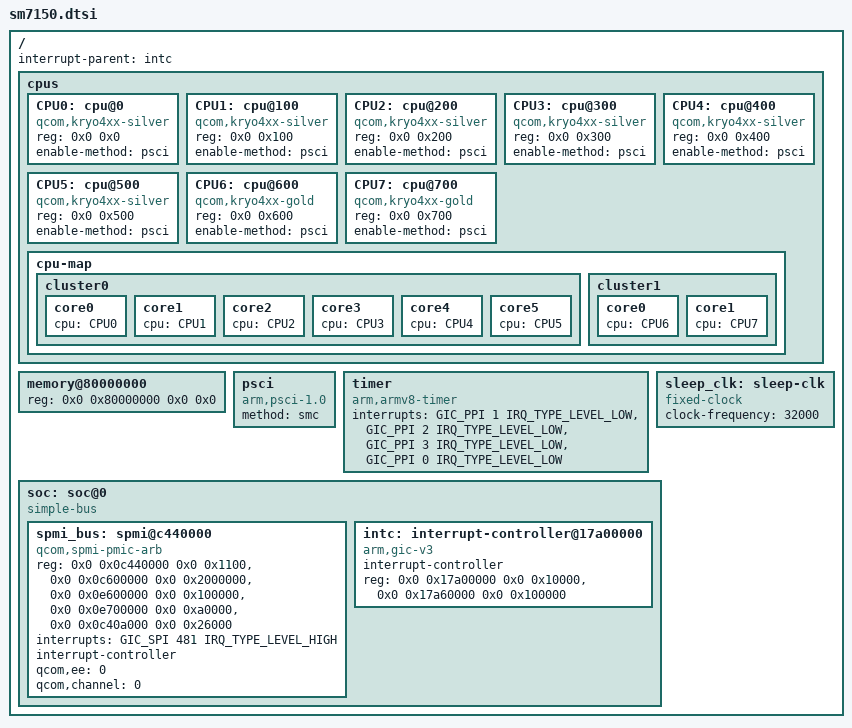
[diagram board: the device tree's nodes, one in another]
// SPDX-License-Identifier: GPL-2.0-only OR BSD-2-Clause

#include <dt-bindings/interrupt-controller/arm-gic.h>

/ {
	#address-cells = <2>;
	#size-cells = <2>;
	interrupt-parent = <&intc>;

	cpus {
		#address-cells = <2>;
		#size-cells = <0>;

		CPU0: cpu@0 {
			device_type = "cpu";
			compatible = "qcom,kryo4xx-silver";
			reg = <0x0 0x0>;
			enable-method = "psci";
		};

		CPU1: cpu@100 {
			device_type = "cpu";
			compatible = "qcom,kryo4xx-silver";
			reg = <0x0 0x100>;
			enable-method = "psci";
		};

		CPU2: cpu@200 {
			device_type = "cpu";
			compatible = "qcom,kryo4xx-silver";
			reg = <0x0 0x200>;
			enable-method = "psci";
		};

		CPU3: cpu@300 {
			device_type = "cpu";
			compatible = "qcom,kryo4xx-silver";
			reg = <0x0 0x300>;
			enable-method = "psci";
		};

		CPU4: cpu@400 {
			device_type = "cpu";
			compatible = "qcom,kryo4xx-silver";
			reg = <0x0 0x400>;
			enable-method = "psci";
		};

		CPU5: cpu@500 {
			device_type = "cpu";
			compatible = "qcom,kryo4xx-silver";
			reg = <0x0 0x500>;
			enable-method = "psci";
		};

		CPU6: cpu@600 {
			device_type = "cpu";
			compatible = "qcom,kryo4xx-gold";
			reg = <0x0 0x600>;
			enable-method = "psci";
		};

		CPU7: cpu@700 {
			device_type = "cpu";
			compatible = "qcom,kryo4xx-gold";
			reg = <0x0 0x700>;
			enable-method = "psci";
		};

		cpu-map {
			cluster0 {
				core0 {
					cpu = <&CPU0>;
				};

				core1 {
					cpu = <&CPU1>;
				};

				core2 {
					cpu = <&CPU2>;
				};

				core3 {
					cpu = <&CPU3>;
				};

				core4 {
					cpu = <&CPU4>;
				};

				core5 {
					cpu = <&CPU5>;
				};
			};

			cluster1 {
				core0 {
					cpu = <&CPU6>;
				};

				core1 {
					cpu = <&CPU7>;
				};
			};
		};
	};

	memory@80000000 {
		device_type = "memory";
		/* Zero-size placeholder: the board DTS supplies the real layout. */
		reg = <0x0 0x80000000 0x0 0x0>;
	};

	psci {
		compatible = "arm,psci-1.0";
		method = "smc";
	};

	timer {
		compatible = "arm,armv8-timer";
		interrupts = <GIC_PPI 1 IRQ_TYPE_LEVEL_LOW>,
			     <GIC_PPI 2 IRQ_TYPE_LEVEL_LOW>,
			     <GIC_PPI 3 IRQ_TYPE_LEVEL_LOW>,
			     <GIC_PPI 0 IRQ_TYPE_LEVEL_LOW>;
	};

	sleep_clk: sleep-clk {
		compatible = "fixed-clock";
		#clock-cells = <0>;
		clock-frequency = <32000>;
	};

	soc: soc@0 {
		compatible = "simple-bus";
		#address-cells = <2>;
		#size-cells = <2>;
		ranges;

		spmi_bus: spmi@c440000 {
			compatible = "qcom,spmi-pmic-arb";
			reg = <0x0 0x0c440000 0x0 0x1100>,	/* core */
			      <0x0 0x0c600000 0x0 0x2000000>,	/* chnls */
			      <0x0 0x0e600000 0x0 0x100000>,	/* obsrvr */
			      <0x0 0x0e700000 0x0 0xa0000>,	/* intr */
			      <0x0 0x0c40a000 0x0 0x26000>;	/* cnfg */
			reg-names = "core", "chnls", "obsrvr", "intr", "cnfg";
			interrupt-names = "periph_irq";
			interrupts = <GIC_SPI 481 IRQ_TYPE_LEVEL_HIGH>;
			interrupt-controller;
			#interrupt-cells = <4>;
			qcom,ee = <0>;
			qcom,channel = <0>;
			#address-cells = <2>;
			#size-cells = <0>;
		};

		intc: interrupt-controller@17a00000 {
			compatible = "arm,gic-v3";
			interrupt-controller;
			#interrupt-cells = <3>;
			reg = <0x0 0x17a00000 0x0 0x10000>,	/* GICD */
			      <0x0 0x17a60000 0x0 0x100000>;	/* GICR */
		};
	};
};

#include "pm6150-sm7150.dtsi"
